AUTOSAR XML (schema 4-3-0)
package /Impl_SWC_DID_ARPkg
  swc implementation Impl_SWC_DID_type: programming-language=C, sw-version=1.0.0, vendor-id=0, behavior=SWC_DID_type_IB
    code-descriptors:
      code SRC: artifact-descriptors=autosar-engineering-object={short-label=EngObject, category=SWSRC}
    resource consumption ResourceConsumption
      memory section Mem_SWC_DID_CODE: size=0, sw-addrmethod=CODE, symbol=CODE
package /Interface_DID_ARPkg
  client server interface IF_DIDReadCDD
    18 x operation:
      CSOP_DIDGet_XWDMode
        4 x arg, all with server-argument-impl-policy=USE-ARGUMENT-TYPE:
          u8_XWDMode: type=uint8, direction=OUT
          u8_DIDSta_XWDMode: type=uint8, direction=OUT
          u16_DIDNum_XWDMode: type=uint16, direction=IN
          u16_DIDLen_XWDMode: type=uint16, direction=IN
      CSOP_DIDGet_DKCKey
        4 x arg, all with server-argument-impl-policy=USE-ARGUMENT-TYPE:
          u8Array8_DKCKey: type=u8Array8_DKCKey_type, direction=OUT
          u8_DIDSta_DKCKey: type=uint8, direction=OUT
          u16_DIDNum_DKCKey: type=uint16, direction=IN
          u16_DIDLen_DKCKey: type=uint16, direction=IN
      CSOP_DIDGet_DynoMode
        4 x arg, all with server-argument-impl-policy=USE-ARGUMENT-TYPE:
          u8_DynoMode: type=uint8, direction=OUT
          u8_DIDSta_DynoMode: type=uint8, direction=OUT
          u16_DIDNum_DynoMode: type=uint16, direction=IN
          u16_DIDLen_DynoMode: type=uint16, direction=IN
      CSOP_DIDGet_TurnLampFRThreCurr
        4 x arg, all with server-argument-impl-policy=USE-ARGUMENT-TYPE:
          u8_TurnLampFRThreCurr: type=uint8, direction=OUT
          u8_DIDSta_TurnLampFRThreCurr: type=uint8, direction=OUT
          u16_DIDNum_TurnLampFRThreCurr: type=uint16, direction=IN
          u16_DIDLen_TurnLampFRThreCurr: type=uint16, direction=IN
      CSOP_DIDGet_TurnLampRRThreCurr
        4 x arg, all with server-argument-impl-policy=USE-ARGUMENT-TYPE:
          u8_TurnLampRRThreCurr: type=uint8, direction=OUT
          u8_DIDSta_TurnLampRRThreCurr: type=uint8, direction=OUT
          u16_DIDNum_TurnLampRRThreCurr: type=uint16, direction=IN
          u16_DIDLen_TurnLampRRThreCurr: type=uint16, direction=IN
      CSOP_DIDGet_TurnLampFLThreCurr
        4 x arg, all with server-argument-impl-policy=USE-ARGUMENT-TYPE:
          u8_TurnLampFLThreCurr: type=uint8, direction=OUT
          u8_DIDSta_TurnLampFLThreCurr: type=uint8, direction=OUT
          u16_DIDNum_TurnLampFLThreCurr: type=uint16, direction=IN
          u16_DIDLen_TurnLampFLThreCurr: type=uint16, direction=IN
      CSOP_DIDGet_TurnLampRLThreCurr
        4 x arg, all with server-argument-impl-policy=USE-ARGUMENT-TYPE:
          u8_TurnLampRLThreCurr: type=uint8, direction=OUT
          u8_DIDSta_TurnLampRLThreCurr: type=uint8, direction=OUT
          u16_DIDNum_TurnLampRLThreCurr: type=uint16, direction=IN
          u16_DIDLen_TurnLampRLThreCurr: type=uint16, direction=IN
      CSOP_DIDGet_FMHTimer
        4 x arg, all with server-argument-impl-policy=USE-ARGUMENT-TYPE:
          u8_FMHTimer: type=uint8, direction=OUT
          u8_DIDSta_FMHTimer: type=uint8, direction=OUT
          u16_DIDNum_FMHTimer: type=uint16, direction=IN
          u16_DIDLen_FMHTimer: type=uint16, direction=IN
      CSOP_DIDGet_AutoLock
        4 x arg, all with server-argument-impl-policy=USE-ARGUMENT-TYPE:
          u8_AutoLock: type=uint8, direction=OUT
          u8_DIDSta_AutoLock: type=uint8, direction=OUT
          u16_DIDNum_AutoLock: type=uint16, direction=IN
          u16_DIDLen_AutoLock: type=uint16, direction=IN
      CSOP_DIDGet_DRLDis
        4 x arg, all with server-argument-impl-policy=USE-ARGUMENT-TYPE:
          u8_DRLDis: type=uint8, direction=OUT
          u8_DIDSta_DRLDis: type=uint8, direction=OUT
          u16_DIDNum_DRLDis: type=uint16, direction=IN
          u16_DIDLen_DRLDis: type=uint16, direction=IN
      CSOP_DIDGet_AutoWipHSpdEN
        4 x arg, all with server-argument-impl-policy=USE-ARGUMENT-TYPE:
          u8_AutoWipHSpdEN: type=uint8, direction=OUT
          u8_DIDSta_AutoWipHSpdEN: type=uint8, direction=OUT
          u16_DIDNum_AutoWipHSpdEN: type=uint16, direction=IN
          u16_DIDLen_AutoWipHSpdEN: type=uint16, direction=IN
      CSOP_DIDGet_WipRLSCmdHoldFilter
        4 x arg, all with server-argument-impl-policy=USE-ARGUMENT-TYPE:
          u8_WipRLSCmdHoldFilter: type=uint8, direction=OUT
          u8_DIDSta_WipRLSCmdHoldFilter: type=uint8, direction=OUT
          u16_DIDNum_WipRLSCmdHoldFilter: type=uint16, direction=IN
          u16_DIDLen_WipRLSCmdHoldFilter: type=uint16, direction=IN
      CSOP_DIDGet_WipRLSCmdCutFilter
        4 x arg, all with server-argument-impl-policy=USE-ARGUMENT-TYPE:
          u8_WipRLSCmdCutFilter: type=uint8, direction=OUT
          u8_DIDSta_WipRLSCmdCutFilter: type=uint8, direction=OUT
          u16_DIDNum_WipRLSCmdCutFilter: type=uint16, direction=IN
          u16_DIDLen_WipRLSCmdCutFilter: type=uint16, direction=IN
      CSOP_DIDGet_USSConfig
        4 x arg, all with server-argument-impl-policy=USE-ARGUMENT-TYPE:
          u8Array16_USSConfig: type=u8Array16_USSConfig_type, direction=OUT
          u8_DIDSta_USSConfig: type=uint8, direction=OUT
          u16_DIDNum_USSConfig: type=uint16, direction=IN
          u16_DIDLen_USSConfig: type=uint16, direction=IN
      CSOP_DIDGet_TireSize
        4 x arg, all with server-argument-impl-policy=USE-ARGUMENT-TYPE:
          u8Array16_TireSize: type=u8Array16_TireSize_type, direction=OUT
          u8_DIDSta_TireSize: type=uint8, direction=OUT
          u16_DIDNum_TireSize: type=uint16, direction=IN
          u16_DIDLen_TireSize: type=uint16, direction=IN
      CSOP_DIDGet_APSFunConfig
        4 x arg, all with server-argument-impl-policy=USE-ARGUMENT-TYPE:
          u8Array16_APSFunConfig: type=u8Array16_APSFunConfig_type, direction=OUT
          u8_DIDSta_APSFunConfig: type=uint8, direction=OUT
          u16_DIDNum_APSFunConfig: type=uint16, direction=IN
          u16_DIDLen_APSFunConfig: type=uint16, direction=IN
      CSOP_DIDGet_OBDReq
        4 x arg, all with server-argument-impl-policy=USE-ARGUMENT-TYPE:
          u8_OBDReq: type=uint8, direction=OUT
          u8_DIDSta_OBDReq: type=uint8, direction=OUT
          u16_DIDNum_OBDReq: type=uint16, direction=IN
          u16_DIDLen_OBDReq: type=uint16, direction=IN
      CSOP_DIDGet_TestGroup
        4 x arg, all with server-argument-impl-policy=USE-ARGUMENT-TYPE:
          u8Array12_TestGroup: type=u8Array12_TestGroup_type, direction=OUT
          u8_DIDSta_TestGroup: type=uint8, direction=OUT
          u16_DIDNum_TestGroup: type=uint16, direction=IN
          u16_DIDLen_TestGroup: type=uint16, direction=IN
  client server interface IF_DIDWriteCDD
    56 x operation:
      CSOP_DIDSet_XWDMode
        arg u16_DIDNum_XWDMode: type=uint16, direction=IN, server-argument-impl-policy=USE-ARGUMENT-TYPE
        arg u16_DIDLen_XWDMode: type=uint16, direction=IN, server-argument-impl-policy=USE-ARGUMENT-TYPE
        arg u8_XWDMode: type=uint8, direction=IN, server-argument-impl-policy=USE-ARGUMENT-TYPE
      CSOP_DIDSet_DKCKey
        arg u16_DIDNum_DKCKey: type=uint16, direction=IN, server-argument-impl-policy=USE-ARGUMENT-TYPE
        arg u16_DIDLen_DKCKey: type=uint16, direction=IN, server-argument-impl-policy=USE-ARGUMENT-TYPE
        arg u8Array8_DKCKey: type=u8Array8_DKCKey_type, direction=IN, server-argument-impl-policy=USE-ARGUMENT-TYPE
      CSOP_DIDSet_DynoMode
        arg u16_DIDNum_DynoMode: type=uint16, direction=IN, server-argument-impl-policy=USE-ARGUMENT-TYPE
        arg u16_DIDLen_DynoMode: type=uint16, direction=IN, server-argument-impl-policy=USE-ARGUMENT-TYPE
        arg u8_DynoMode: type=uint8, direction=IN, server-argument-impl-policy=USE-ARGUMENT-TYPE
      CSOP_DIDSet_APPPedalZP
        arg u16_DIDNum_APPPedalZP: type=uint16, direction=IN, server-argument-impl-policy=USE-ARGUMENT-TYPE
        arg u16_DIDLen_APPPedalZP: type=uint16, direction=IN, server-argument-impl-policy=USE-ARGUMENT-TYPE
        arg u8Array3_APPPedalZP: type=u8Array3_APPPedalZP_type, direction=IN, server-argument-impl-policy=USE-ARGUMENT-TYPE
      CSOP_DIDSet_NVMPedalZP
        arg u16_DIDNum_NVMPedalZP: type=uint16, direction=IN, server-argument-impl-policy=USE-ARGUMENT-TYPE
        arg u16_DIDLen_NVMPedalZP: type=uint16, direction=IN, server-argument-impl-policy=USE-ARGUMENT-TYPE
        arg u8Array3_NVMPedalZP: type=u8Array3_NVMPedalZP_type, direction=IN, server-argument-impl-policy=USE-ARGUMENT-TYPE
      CSOP_DIDSet_TurnLampFRThreCurr
        arg u16_DIDNum_TurnLampFRThreCurr: type=uint16, direction=IN, server-argument-impl-policy=USE-ARGUMENT-TYPE
        arg u16_DIDLen_TurnLampFRThreCurr: type=uint16, direction=IN, server-argument-impl-policy=USE-ARGUMENT-TYPE
        arg u8_TurnLampFRThreCurr: type=uint8, direction=IN, server-argument-impl-policy=USE-ARGUMENT-TYPE
      CSOP_DIDSet_TurnLampRRThreCurr
        arg u16_DIDNum_TurnLampRRThreCurr: type=uint16, direction=IN, server-argument-impl-policy=USE-ARGUMENT-TYPE
        arg u16_DIDLen_TurnLampRRThreCurr: type=uint16, direction=IN, server-argument-impl-policy=USE-ARGUMENT-TYPE
        arg u8_TurnLampRRThreCurr: type=uint8, direction=IN, server-argument-impl-policy=USE-ARGUMENT-TYPE
      CSOP_DIDSet_TurnLampFLThreCurr
        arg u16_DIDNum_TurnLampFLThreCurr: type=uint16, direction=IN, server-argument-impl-policy=USE-ARGUMENT-TYPE
        arg u16_DIDLen_TurnLampFLThreCurr: type=uint16, direction=IN, server-argument-impl-policy=USE-ARGUMENT-TYPE
        arg u8_TurnLampFLThreCurr: type=uint8, direction=IN, server-argument-impl-policy=USE-ARGUMENT-TYPE
      CSOP_DIDSet_TurnLampRLThreCurr
        arg u16_DIDNum_TurnLampRLThreCurr: type=uint16, direction=IN, server-argument-impl-policy=USE-ARGUMENT-TYPE
        arg u16_DIDLen_TurnLampRLThreCurr: type=uint16, direction=IN, server-argument-impl-policy=USE-ARGUMENT-TYPE
        arg u8_TurnLampRLThreCurr: type=uint8, direction=IN, server-argument-impl-policy=USE-ARGUMENT-TYPE
      CSOP_DIDSet_FMHTimer
        arg u16_DIDNum_FMHTimer: type=uint16, direction=IN, server-argument-impl-policy=USE-ARGUMENT-TYPE
        arg u16_DIDLen_FMHTimer: type=uint16, direction=IN, server-argument-impl-policy=USE-ARGUMENT-TYPE
        arg u8_FMHTimer: type=uint8, direction=IN, server-argument-impl-policy=USE-ARGUMENT-TYPE
      CSOP_DIDSet_AutoLock
        arg u16_DIDNum_AutoLock: type=uint16, direction=IN, server-argument-impl-policy=USE-ARGUMENT-TYPE
        arg u16_DIDLen_AutoLock: type=uint16, direction=IN, server-argument-impl-policy=USE-ARGUMENT-TYPE
        arg u8_AutoLock: type=uint8, direction=IN, server-argument-impl-policy=USE-ARGUMENT-TYPE
      CSOP_DIDSet_DRLDis
        arg u16_DIDNum_DRLDis: type=uint16, direction=IN, server-argument-impl-policy=USE-ARGUMENT-TYPE
        arg u16_DIDLen_DRLDis: type=uint16, direction=IN, server-argument-impl-policy=USE-ARGUMENT-TYPE
        arg u8_DRLDis: type=uint8, direction=IN, server-argument-impl-policy=USE-ARGUMENT-TYPE
      CSOP_DIDSet_AutoWipHSpdEN
        arg u16_DIDNum_AutoWipHSpdEN: type=uint16, direction=IN, server-argument-impl-policy=USE-ARGUMENT-TYPE
        arg u16_DIDLen_AutoWipHSpdEN: type=uint16, direction=IN, server-argument-impl-policy=USE-ARGUMENT-TYPE
        arg u8_AutoWipHSpdEN: type=uint8, direction=IN, server-argument-impl-policy=USE-ARGUMENT-TYPE
      CSOP_DIDSet_WipRLSCmdHoldFilter
        arg u16_DIDNum_WipRLSCmdHoldFilter: type=uint16, direction=IN, server-argument-impl-policy=USE-ARGUMENT-TYPE
        arg u16_DIDLen_WipRLSCmdHoldFilter: type=uint16, direction=IN, server-argument-impl-policy=USE-ARGUMENT-TYPE
        arg u8_WipRLSCmdHoldFilter: type=uint8, direction=IN, server-argument-impl-policy=USE-ARGUMENT-TYPE
      CSOP_DIDSet_WipRLSCmdCutFilter
        arg u16_DIDNum_WipRLSCmdCutFilter: type=uint16, direction=IN, server-argument-impl-policy=USE-ARGUMENT-TYPE
        arg u16_DIDLen_WipRLSCmdCutFilter: type=uint16, direction=IN, server-argument-impl-policy=USE-ARGUMENT-TYPE
        arg u8_WipRLSCmdCutFilter: type=uint8, direction=IN, server-argument-impl-policy=USE-ARGUMENT-TYPE
      CSOP_DIDSet_LFSensorID
        arg u16_DIDNum_LFSensorID: type=uint16, direction=IN, server-argument-impl-policy=USE-ARGUMENT-TYPE
        arg u16_DIDLen_LFSensorID: type=uint16, direction=IN, server-argument-impl-policy=USE-ARGUMENT-TYPE
        arg u8Array4_LFSensorID: type=u8Array4_LFSensorID_type, direction=IN, server-argument-impl-policy=USE-ARGUMENT-TYPE
      CSOP_DIDSet_RFSensorID
        arg u16_DIDNum_RFSensorID: type=uint16, direction=IN, server-argument-impl-policy=USE-ARGUMENT-TYPE
        arg u16_DIDLen_RFSensorID: type=uint16, direction=IN, server-argument-impl-policy=USE-ARGUMENT-TYPE
        arg u8Array4_RFSensorID: type=u8Array4_RFSensorID_type, direction=IN, server-argument-impl-policy=USE-ARGUMENT-TYPE
      CSOP_DIDSet_LRSensorID
        arg u16_DIDNum_LRSensorID: type=uint16, direction=IN, server-argument-impl-policy=USE-ARGUMENT-TYPE
        arg u16_DIDLen_LRSensorID: type=uint16, direction=IN, server-argument-impl-policy=USE-ARGUMENT-TYPE
        arg u8Array4_LRSensorID: type=u8Array4_LRSensorID_type, direction=IN, server-argument-impl-policy=USE-ARGUMENT-TYPE
      CSOP_DIDSet_RRSensorID
        arg u16_DIDNum_RRSensorID: type=uint16, direction=IN, server-argument-impl-policy=USE-ARGUMENT-TYPE
        arg u16_DIDLen_RRSensorID: type=uint16, direction=IN, server-argument-impl-policy=USE-ARGUMENT-TYPE
        arg u8Array4_RRSensorID: type=u8Array4_RRSensorID_type, direction=IN, server-argument-impl-policy=USE-ARGUMENT-TYPE
      CSOP_DIDSet_WhlPres
        arg u16_DIDNum_WhlPres: type=uint16, direction=IN, server-argument-impl-policy=USE-ARGUMENT-TYPE
        arg u16_DIDLen_WhlPres: type=uint16, direction=IN, server-argument-impl-policy=USE-ARGUMENT-TYPE
        arg u8Array4_WhlPres: type=u8Array4_WhlPres_type, direction=IN, server-argument-impl-policy=USE-ARGUMENT-TYPE
      CSOP_DIDSet_WhlTmp
        arg u16_DIDNum_WhlTmp: type=uint16, direction=IN, server-argument-impl-policy=USE-ARGUMENT-TYPE
        arg u16_DIDLen_WhlTmp: type=uint16, direction=IN, server-argument-impl-policy=USE-ARGUMENT-TYPE
        arg u8Array4_WhlTmp: type=u8Array4_WhlTmp_type, direction=IN, server-argument-impl-policy=USE-ARGUMENT-TYPE
      CSOP_DIDSet_WhlSensorBattSta
        arg u16_DIDNum_WhlSensorBattSta: type=uint16, direction=IN, server-argument-impl-policy=USE-ARGUMENT-TYPE
        arg u16_DIDLen_WhlSensorBattSta: type=uint16, direction=IN, server-argument-impl-policy=USE-ARGUMENT-TYPE
        arg u8_WhlSensorBattSta: type=uint8, direction=IN, server-argument-impl-policy=USE-ARGUMENT-TYPE
      CSOP_DIDSet_LFLowPresThre
        arg u16_DIDNum_LFLowPresThre: type=uint16, direction=IN, server-argument-impl-policy=USE-ARGUMENT-TYPE
        arg u16_DIDLen_LFLowPresThre: type=uint16, direction=IN, server-argument-impl-policy=USE-ARGUMENT-TYPE
        arg u8_LFLowPresThre: type=uint8, direction=IN, server-argument-impl-policy=USE-ARGUMENT-TYPE
      CSOP_DIDSet_RFLowPresThre
        arg u16_DIDNum_RFLowPresThre: type=uint16, direction=IN, server-argument-impl-policy=USE-ARGUMENT-TYPE
        arg u16_DIDLen_RFLowPresThre: type=uint16, direction=IN, server-argument-impl-policy=USE-ARGUMENT-TYPE
        arg u8_RFLowPresThre: type=uint8, direction=IN, server-argument-impl-policy=USE-ARGUMENT-TYPE
      CSOP_DIDSet_LRLowPresThre
        arg u16_DIDNum_LRLowPresThre: type=uint16, direction=IN, server-argument-impl-policy=USE-ARGUMENT-TYPE
        arg u16_DIDLen_LRLowPresThre: type=uint16, direction=IN, server-argument-impl-policy=USE-ARGUMENT-TYPE
        arg u8_LRLowPresThre: type=uint8, direction=IN, server-argument-impl-policy=USE-ARGUMENT-TYPE
      CSOP_DIDSet_RRLowPresThre
        arg u16_DIDNum_RRLowPresThre: type=uint16, direction=IN, server-argument-impl-policy=USE-ARGUMENT-TYPE
        arg u16_DIDLen_RRLowPresThre: type=uint16, direction=IN, server-argument-impl-policy=USE-ARGUMENT-TYPE
        arg u8_RRLowPresThre: type=uint8, direction=IN, server-argument-impl-policy=USE-ARGUMENT-TYPE
      CSOP_DIDSet_SensorMode
        arg u16_DIDNum_SensorMode: type=uint16, direction=IN, server-argument-impl-policy=USE-ARGUMENT-TYPE
        arg u16_DIDLen_SensorMode: type=uint16, direction=IN, server-argument-impl-policy=USE-ARGUMENT-TYPE
        arg u8_SensorMode: type=uint8, direction=IN, server-argument-impl-policy=USE-ARGUMENT-TYPE
      CSOP_DIDSet_TPMSLearnSta
        arg u16_DIDNum_TPMSLearnSta: type=uint16, direction=IN, server-argument-impl-policy=USE-ARGUMENT-TYPE
        arg u16_DIDLen_TPMSLearnSta: type=uint16, direction=IN, server-argument-impl-policy=USE-ARGUMENT-TYPE
        arg u8_TPMSLearnSta: type=uint8, direction=IN, server-argument-impl-policy=USE-ARGUMENT-TYPE
      CSOP_DIDSet_USSConfig
        arg u16_DIDNum_USSConfig: type=uint16, direction=IN, server-argument-impl-policy=USE-ARGUMENT-TYPE
        arg u16_DIDLen_USSConfig: type=uint16, direction=IN, server-argument-impl-policy=USE-ARGUMENT-TYPE
        arg u8Array16_USSConfig: type=u8Array16_USSConfig_type, direction=IN, server-argument-impl-policy=USE-ARGUMENT-TYPE
      CSOP_DIDSet_TireSize
        arg u16_DIDNum_TireSize: type=uint16, direction=IN, server-argument-impl-policy=USE-ARGUMENT-TYPE
        arg u16_DIDLen_TireSize: type=uint16, direction=IN, server-argument-impl-policy=USE-ARGUMENT-TYPE
        arg u8Array16_TireSize: type=u8Array16_TireSize_type, direction=IN, server-argument-impl-policy=USE-ARGUMENT-TYPE
      CSOP_DIDSet_APSFunConfig
        arg u16_DIDNum_APSFunConfig: type=uint16, direction=IN, server-argument-impl-policy=USE-ARGUMENT-TYPE
        arg u16_DIDLen_APSFunConfig: type=uint16, direction=IN, server-argument-impl-policy=USE-ARGUMENT-TYPE
        arg u8Array16_APSFunConfig: type=u8Array16_APSFunConfig_type, direction=IN, server-argument-impl-policy=USE-ARGUMENT-TYPE
      CSOP_DIDSet_VSS
        arg u16_DIDNum_VSS: type=uint16, direction=IN, server-argument-impl-policy=USE-ARGUMENT-TYPE
        arg u16_DIDLen_VSS: type=uint16, direction=IN, server-argument-impl-policy=USE-ARGUMENT-TYPE
        arg u8_VSS: type=uint8, direction=IN, server-argument-impl-policy=USE-ARGUMENT-TYPE
      CSOP_DIDSet_OBDReq
        arg u16_DIDNum_OBDReq: type=uint16, direction=IN, server-argument-impl-policy=USE-ARGUMENT-TYPE
        arg u16_DIDLen_OBDReq: type=uint16, direction=IN, server-argument-impl-policy=USE-ARGUMENT-TYPE
        arg u8_OBDReq: type=uint8, direction=IN, server-argument-impl-policy=USE-ARGUMENT-TYPE
      CSOP_DIDSet_RUNTM
        arg u16_DIDNum_RUNTM: type=uint16, direction=IN, server-argument-impl-policy=USE-ARGUMENT-TYPE
        arg u16_DIDLen_RUNTM: type=uint16, direction=IN, server-argument-impl-policy=USE-ARGUMENT-TYPE
        arg u8Array2_RUNTM: type=u8Array2_RUNTM_type, direction=IN, server-argument-impl-policy=USE-ARGUMENT-TYPE
      CSOP_DIDSet_MILDIST
        arg u16_DIDNum_MILDIST: type=uint16, direction=IN, server-argument-impl-policy=USE-ARGUMENT-TYPE
        arg u16_DIDLen_MILDIST: type=uint16, direction=IN, server-argument-impl-policy=USE-ARGUMENT-TYPE
        arg u8Array2_MILDIST: type=u8Array2_MILDIST_type, direction=IN, server-argument-impl-policy=USE-ARGUMENT-TYPE
      CSOP_DIDSet_CLRDIST
        arg u16_DIDNum_CLRDIST: type=uint16, direction=IN, server-argument-impl-policy=USE-ARGUMENT-TYPE
        arg u16_DIDLen_CLRDIST: type=uint16, direction=IN, server-argument-impl-policy=USE-ARGUMENT-TYPE
        arg u8Array2_CLRDIST: type=u8Array2_CLRDIST_type, direction=IN, server-argument-impl-policy=USE-ARGUMENT-TYPE
      CSOP_DIDSet_APPD
        arg u16_DIDNum_APPD: type=uint16, direction=IN, server-argument-impl-policy=USE-ARGUMENT-TYPE
        arg u16_DIDLen_APPD: type=uint16, direction=IN, server-argument-impl-policy=USE-ARGUMENT-TYPE
        arg u8_APPD: type=uint8, direction=IN, server-argument-impl-policy=USE-ARGUMENT-TYPE
      CSOP_DIDSet_APPE
        arg u16_DIDNum_APPE: type=uint16, direction=IN, server-argument-impl-policy=USE-ARGUMENT-TYPE
        arg u16_DIDLen_APPE: type=uint16, direction=IN, server-argument-impl-policy=USE-ARGUMENT-TYPE
        arg u8_APPE: type=uint8, direction=IN, server-argument-impl-policy=USE-ARGUMENT-TYPE
      CSOP_DIDSet_ODOMETER
        arg u16_DIDNum_ODOMETER: type=uint16, direction=IN, server-argument-impl-policy=USE-ARGUMENT-TYPE
        arg u16_DIDLen_ODOMETER: type=uint16, direction=IN, server-argument-impl-policy=USE-ARGUMENT-TYPE
        arg u8Array4_ODOMETER: type=u8Array4_ODOMETER_type, direction=IN, server-argument-impl-policy=USE-ARGUMENT-TYPE
      CSOP_DIDSet_NUMPSATRIPSFLTMEMCLR
        arg u16_DIDNum_NUMPSATRIPSFLTMEMCLR: type=uint16, direction=IN, server-argument-impl-policy=USE-ARGUMENT-TYPE
        arg u16_DIDLen_NUMPSATRIPSFLTMEMCLR: type=uint16, direction=IN, server-argument-impl-policy=USE-ARGUMENT-TYPE
        arg u8Array2_NUMPSATRIPSFLTMEMCLR: type=u8Array2_NUMPSATRIPSFLTMEMCLR_type, direction=IN, server-argument-impl-policy=USE-ARGUMENT-TYPE
      CSOP_DIDSet_VIN
        arg u16_DIDNum_VIN: type=uint16, direction=IN, server-argument-impl-policy=USE-ARGUMENT-TYPE
        arg u16_DIDLen_VIN: type=uint16, direction=IN, server-argument-impl-policy=USE-ARGUMENT-TYPE
        arg u8Array17_VIN: type=u8Array17_VIN_type, direction=IN, server-argument-impl-policy=USE-ARGUMENT-TYPE
      CSOP_DIDSet_CALID
        arg u16_DIDNum_CALID: type=uint16, direction=IN, server-argument-impl-policy=USE-ARGUMENT-TYPE
        arg u16_DIDLen_CALID: type=uint16, direction=IN, server-argument-impl-policy=USE-ARGUMENT-TYPE
        arg u8Array16_CALID: type=u8Array16_CALID_type, direction=IN, server-argument-impl-policy=USE-ARGUMENT-TYPE
      CSOP_DIDSet_ECUNAME
        arg u16_DIDNum_ECUNAME: type=uint16, direction=IN, server-argument-impl-policy=USE-ARGUMENT-TYPE
        arg u16_DIDLen_ECUNAME: type=uint16, direction=IN, server-argument-impl-policy=USE-ARGUMENT-TYPE
        arg u8Array20_ECUNAME: type=u8Array20_ECUNAME_type, direction=IN, server-argument-impl-policy=USE-ARGUMENT-TYPE
      CSOP_DIDSet_ProtocolId
        arg u16_DIDNum_ProtocolId: type=uint16, direction=IN, server-argument-impl-policy=USE-ARGUMENT-TYPE
        arg u16_DIDLen_ProtocolId: type=uint16, direction=IN, server-argument-impl-policy=USE-ARGUMENT-TYPE
        arg u8_ProtocolId: type=uint8, direction=IN, server-argument-impl-policy=USE-ARGUMENT-TYPE
      CSOP_DIDSet_TestGroup
        arg u16_DIDNum_TestGroup: type=uint16, direction=IN, server-argument-impl-policy=USE-ARGUMENT-TYPE
        arg u16_DIDLen_TestGroup: type=uint16, direction=IN, server-argument-impl-policy=USE-ARGUMENT-TYPE
        arg u8Array12_TestGroup: type=u8Array12_TestGroup_type, direction=IN, server-argument-impl-policy=USE-ARGUMENT-TYPE
      CSOP_DIDSet_PSA
        arg u16_DIDNum_PSA: type=uint16, direction=IN, server-argument-impl-policy=USE-ARGUMENT-TYPE
        arg u16_DIDLen_PSA: type=uint16, direction=IN, server-argument-impl-policy=USE-ARGUMENT-TYPE
        arg u8Array24_PSA: type=u8Array24_PSA_type, direction=IN, server-argument-impl-policy=USE-ARGUMENT-TYPE
      CSOP_DIDSet_PKE
        arg u16_DIDNum_PKE: type=uint16, direction=IN, server-argument-impl-policy=USE-ARGUMENT-TYPE
        arg u16_DIDLen_PKE: type=uint16, direction=IN, server-argument-impl-policy=USE-ARGUMENT-TYPE
        arg u8Array8_PKE: type=u8Array8_PKE_type, direction=IN, server-argument-impl-policy=USE-ARGUMENT-TYPE
      CSOP_DIDSet_CDEODT
        arg u16_DIDNum_CDEODT: type=uint16, direction=IN, server-argument-impl-policy=USE-ARGUMENT-TYPE
        arg u16_DIDLen_CDEODT: type=uint16, direction=IN, server-argument-impl-policy=USE-ARGUMENT-TYPE
        arg u8Array8_CDEODT: type=u8Array8_CDEODT_type, direction=IN, server-argument-impl-policy=USE-ARGUMENT-TYPE
      CSOP_DIDSet_QTYPSATRIPS
        arg u16_DIDNum_QTYPSATRIPS: type=uint16, direction=IN, server-argument-impl-policy=USE-ARGUMENT-TYPE
        arg u16_DIDLen_QTYPSATRIPS: type=uint16, direction=IN, server-argument-impl-policy=USE-ARGUMENT-TYPE
        arg u8Array8_QTYPSATRIPS: type=u8Array8_QTYPSATRIPS_type, direction=IN, server-argument-impl-policy=USE-ARGUMENT-TYPE
      CSOP_DIDSet_DKCSta
        arg u16_DIDNum_DKCSta: type=uint16, direction=IN, server-argument-impl-policy=USE-ARGUMENT-TYPE
        arg u16_DIDLen_DKCSta: type=uint16, direction=IN, server-argument-impl-policy=USE-ARGUMENT-TYPE
        arg u8Array2_DKCSta: type=u8Array2_DKCSta_type, direction=IN, server-argument-impl-policy=USE-ARGUMENT-TYPE
      CSOP_DIDSet_DKCBLESta
        arg u16_DIDNum_DKCBLESta: type=uint16, direction=IN, server-argument-impl-policy=USE-ARGUMENT-TYPE
        arg u16_DIDLen_DKCBLESta: type=uint16, direction=IN, server-argument-impl-policy=USE-ARGUMENT-TYPE
        arg u8Array2_DKCBLESta: type=u8Array2_DKCBLESta_type, direction=IN, server-argument-impl-policy=USE-ARGUMENT-TYPE
      CSOP_DIDSet_UWBAnchorSta
        arg u16_DIDNum_UWBAnchorSta: type=uint16, direction=IN, server-argument-impl-policy=USE-ARGUMENT-TYPE
        arg u16_DIDLen_UWBAnchorSta: type=uint16, direction=IN, server-argument-impl-policy=USE-ARGUMENT-TYPE
        arg u8Array93_UWBAnchorSta: type=u8Array93_UWBAnchorSta_type, direction=IN, server-argument-impl-policy=USE-ARGUMENT-TYPE
      CSOP_DIDSet_LIDAAnchorSta
        arg u16_DIDNum_LIDAAnchorSta: type=uint16, direction=IN, server-argument-impl-policy=USE-ARGUMENT-TYPE
        arg u16_DIDLen_LIDAAnchorSta: type=uint16, direction=IN, server-argument-impl-policy=USE-ARGUMENT-TYPE
        arg u8Array21_LIDAAnchorSta: type=u8Array21_LIDAAnchorSta_type, direction=IN, server-argument-impl-policy=USE-ARGUMENT-TYPE
      CSOP_DIDSet_DoorNFCAnchorSta
        arg u16_DIDNum_DoorNFCAnchorSta: type=uint16, direction=IN, server-argument-impl-policy=USE-ARGUMENT-TYPE
        arg u16_DIDLen_DoorNFCAnchorSta: type=uint16, direction=IN, server-argument-impl-policy=USE-ARGUMENT-TYPE
        arg u8Array21_DoorNFCAnchorSta: type=u8Array21_DoorNFCAnchorSta_type, direction=IN, server-argument-impl-policy=USE-ARGUMENT-TYPE
      CSOP_DIDSet_UIDSta
        arg u16_DIDNum_UIDSta: type=uint16, direction=IN, server-argument-impl-policy=USE-ARGUMENT-TYPE
        arg u16_DIDLen_UIDSta: type=uint16, direction=IN, server-argument-impl-policy=USE-ARGUMENT-TYPE
        arg u8Array26_UIDSta: type=u8Array26_UIDSta_type, direction=IN, server-argument-impl-policy=USE-ARGUMENT-TYPE
      CSOP_DIDSet_FDDKCCoordXY
        arg u16_DIDNum_FDDKCCoordXY: type=uint16, direction=IN, server-argument-impl-policy=USE-ARGUMENT-TYPE
        arg u16_DIDLen_FDDKCCoordXY: type=uint16, direction=IN, server-argument-impl-policy=USE-ARGUMENT-TYPE
        arg u8Array3_FDDKCCoordXY: type=u8Array3_FDDKCCoordXY_type, direction=IN, server-argument-impl-policy=USE-ARGUMENT-TYPE
package /SWC_DID_ARPkg
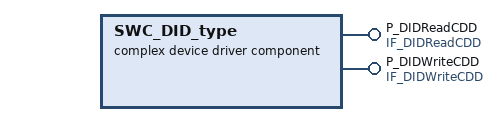
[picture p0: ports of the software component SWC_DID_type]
  complex device driver sw component type SWC_DID_type
    provide port P_DIDReadCDD: provided-interface=IF_DIDReadCDD
    provide port P_DIDWriteCDD: provided-interface=IF_DIDWriteCDD
    behavior SWC_DID_type_IB: handle-termination-and-restart=NO-SUPPORT
      74 x operation invoked event:
        oie_P_DIDReadCDD_CSOP_DIDGet_XWDMode: start-on-event=run_DIDGet_XWDMode, operation=P_DIDReadCDD.CSOP_DIDGet_XWDMode
        oie_P_DIDWriteCDD_CSOP_DIDSet_XWDMode: start-on-event=run_DIDSet_XWDMode, operation=P_DIDWriteCDD.CSOP_DIDSet_XWDMode
        oie_P_DIDReadCDD_CSOP_DIDGet_DKCKey: start-on-event=run_DIDGet_DKCKey, operation=P_DIDReadCDD.CSOP_DIDGet_DKCKey
        oie_P_DIDWriteCDD_CSOP_DIDSet_DKCKey: start-on-event=run_DIDSet_DKCKey, operation=P_DIDWriteCDD.CSOP_DIDSet_DKCKey
        oie_P_DIDReadCDD_CSOP_DIDGet_DynoMode: start-on-event=run_DIDGet_DynoMode, operation=P_DIDReadCDD.CSOP_DIDGet_DynoMode
        oie_P_DIDWriteCDD_CSOP_DIDSet_DynoMode: start-on-event=run_DIDSet_DynoMode, operation=P_DIDWriteCDD.CSOP_DIDSet_DynoMode
        oie_P_DIDWriteCDD_CSOP_DIDSet_APPPedalZP: start-on-event=run_DIDSet_APPPedalZP, operation=P_DIDWriteCDD.CSOP_DIDSet_APPPedalZP
        oie_P_DIDWriteCDD_CSOP_DIDSet_NVMPedalZP: start-on-event=run_DIDSet_NVMPedalZP, operation=P_DIDWriteCDD.CSOP_DIDSet_NVMPedalZP
        oie_P_DIDReadCDD_CSOP_DIDGet_TurnLampFRThreCurr: start-on-event=run_DIDGet_TurnLampFRThreCurr, operation=P_DIDReadCDD.CSOP_DIDGet_TurnLampFRThreCurr
        oie_P_DIDWriteCDD_CSOP_DIDSet_TurnLampFRThreCurr: start-on-event=run_DIDSet_TurnLampFRThreCurr, operation=P_DIDWriteCDD.CSOP_DIDSet_TurnLampFRThreCurr
        oie_P_DIDReadCDD_CSOP_DIDGet_TurnLampRRThreCurr: start-on-event=run_DIDGet_TurnLampRRThreCurr, operation=P_DIDReadCDD.CSOP_DIDGet_TurnLampRRThreCurr
        oie_P_DIDWriteCDD_CSOP_DIDSet_TurnLampRRThreCurr: start-on-event=run_DIDSet_TurnLampRRThreCurr, operation=P_DIDWriteCDD.CSOP_DIDSet_TurnLampRRThreCurr
        oie_P_DIDReadCDD_CSOP_DIDGet_TurnLampFLThreCurr: start-on-event=run_DIDGet_TurnLampFLThreCurr, operation=P_DIDReadCDD.CSOP_DIDGet_TurnLampFLThreCurr
        oie_P_DIDWriteCDD_CSOP_DIDSet_TurnLampFLThreCurr: start-on-event=run_DIDSet_TurnLampFLThreCurr, operation=P_DIDWriteCDD.CSOP_DIDSet_TurnLampFLThreCurr
        oie_P_DIDReadCDD_CSOP_DIDGet_TurnLampRLThreCurr: start-on-event=run_DIDGet_TurnLampRLThreCurr, operation=P_DIDReadCDD.CSOP_DIDGet_TurnLampRLThreCurr
        oie_P_DIDWriteCDD_CSOP_DIDSet_TurnLampRLThreCurr: start-on-event=run_DIDSet_TurnLampRLThreCurr, operation=P_DIDWriteCDD.CSOP_DIDSet_TurnLampRLThreCurr
        oie_P_DIDReadCDD_CSOP_DIDGet_FMHTimer: start-on-event=run_DIDGet_FMHTimer, operation=P_DIDReadCDD.CSOP_DIDGet_FMHTimer
        oie_P_DIDWriteCDD_CSOP_DIDSet_FMHTimer: start-on-event=run_DIDSet_FMHTimer, operation=P_DIDWriteCDD.CSOP_DIDSet_FMHTimer
        oie_P_DIDReadCDD_CSOP_DIDGet_AutoLock: start-on-event=run_DIDGet_AutoLock, operation=P_DIDReadCDD.CSOP_DIDGet_AutoLock
        oie_P_DIDWriteCDD_CSOP_DIDSet_AutoLock: start-on-event=run_DIDSet_AutoLock, operation=P_DIDWriteCDD.CSOP_DIDSet_AutoLock
        oie_P_DIDReadCDD_CSOP_DIDGet_DRLDis: start-on-event=run_DIDGet_DRLDis, operation=P_DIDReadCDD.CSOP_DIDGet_DRLDis
        oie_P_DIDWriteCDD_CSOP_DIDSet_DRLDis: start-on-event=run_DIDSet_DRLDis, operation=P_DIDWriteCDD.CSOP_DIDSet_DRLDis
        oie_P_DIDReadCDD_CSOP_DIDGet_AutoWipHSpdEN: start-on-event=run_DIDGet_AutoWipHSpdEN, operation=P_DIDReadCDD.CSOP_DIDGet_AutoWipHSpdEN
        oie_P_DIDWriteCDD_CSOP_DIDSet_AutoWipHSpdEN: start-on-event=run_DIDSet_AutoWipHSpdEN, operation=P_DIDWriteCDD.CSOP_DIDSet_AutoWipHSpdEN
        oie_P_DIDReadCDD_CSOP_DIDGet_WipRLSCmdHoldFilter: start-on-event=run_DIDGet_WipRLSCmdHoldFilter, operation=P_DIDReadCDD.CSOP_DIDGet_WipRLSCmdHoldFilter
        oie_P_DIDWriteCDD_CSOP_DIDSet_WipRLSCmdHoldFilter: start-on-event=run_DIDSet_WipRLSCmdHoldFilter, operation=P_DIDWriteCDD.CSOP_DIDSet_WipRLSCmdHoldFilter
        oie_P_DIDReadCDD_CSOP_DIDGet_WipRLSCmdCutFilter: start-on-event=run_DIDGet_WipRLSCmdCutFilter, operation=P_DIDReadCDD.CSOP_DIDGet_WipRLSCmdCutFilter
        oie_P_DIDWriteCDD_CSOP_DIDSet_WipRLSCmdCutFilter: start-on-event=run_DIDSet_WipRLSCmdCutFilter, operation=P_DIDWriteCDD.CSOP_DIDSet_WipRLSCmdCutFilter
        oie_P_DIDWriteCDD_CSOP_DIDSet_LFSensorID: start-on-event=run_DIDSet_LFSensorID, operation=P_DIDWriteCDD.CSOP_DIDSet_LFSensorID
        oie_P_DIDWriteCDD_CSOP_DIDSet_RFSensorID: start-on-event=run_DIDSet_RFSensorID, operation=P_DIDWriteCDD.CSOP_DIDSet_RFSensorID
        oie_P_DIDWriteCDD_CSOP_DIDSet_LRSensorID: start-on-event=run_DIDSet_LRSensorID, operation=P_DIDWriteCDD.CSOP_DIDSet_LRSensorID
        oie_P_DIDWriteCDD_CSOP_DIDSet_RRSensorID: start-on-event=run_DIDSet_RRSensorID, operation=P_DIDWriteCDD.CSOP_DIDSet_RRSensorID
        oie_P_DIDWriteCDD_CSOP_DIDSet_WhlPres: start-on-event=run_DIDSet_WhlPres, operation=P_DIDWriteCDD.CSOP_DIDSet_WhlPres
        oie_P_DIDWriteCDD_CSOP_DIDSet_WhlTmp: start-on-event=run_DIDSet_WhlTmp, operation=P_DIDWriteCDD.CSOP_DIDSet_WhlTmp
        oie_P_DIDWriteCDD_CSOP_DIDSet_WhlSensorBattSta: start-on-event=run_DIDSet_WhlSensorBattSta, operation=P_DIDWriteCDD.CSOP_DIDSet_WhlSensorBattSta
        oie_P_DIDWriteCDD_CSOP_DIDSet_LFLowPresThre: start-on-event=run_DIDSet_LFLowPresThre, operation=P_DIDWriteCDD.CSOP_DIDSet_LFLowPresThre
        oie_P_DIDWriteCDD_CSOP_DIDSet_RFLowPresThre: start-on-event=run_DIDSet_RFLowPresThre, operation=P_DIDWriteCDD.CSOP_DIDSet_RFLowPresThre
        oie_P_DIDWriteCDD_CSOP_DIDSet_LRLowPresThre: start-on-event=run_DIDSet_LRLowPresThre, operation=P_DIDWriteCDD.CSOP_DIDSet_LRLowPresThre
        oie_P_DIDWriteCDD_CSOP_DIDSet_RRLowPresThre: start-on-event=run_DIDSet_RRLowPresThre, operation=P_DIDWriteCDD.CSOP_DIDSet_RRLowPresThre
        oie_P_DIDWriteCDD_CSOP_DIDSet_SensorMode: start-on-event=run_DIDSet_SensorMode, operation=P_DIDWriteCDD.CSOP_DIDSet_SensorMode
        oie_P_DIDWriteCDD_CSOP_DIDSet_TPMSLearnSta: start-on-event=run_DIDSet_TPMSLearnSta, operation=P_DIDWriteCDD.CSOP_DIDSet_TPMSLearnSta
        oie_P_DIDReadCDD_CSOP_DIDGet_USSConfig: start-on-event=run_DIDGet_USSConfig, operation=P_DIDReadCDD.CSOP_DIDGet_USSConfig
        oie_P_DIDWriteCDD_CSOP_DIDSet_USSConfig: start-on-event=run_DIDSet_USSConfig, operation=P_DIDWriteCDD.CSOP_DIDSet_USSConfig
        oie_P_DIDReadCDD_CSOP_DIDGet_TireSize: start-on-event=run_DIDGet_TireSize, operation=P_DIDReadCDD.CSOP_DIDGet_TireSize
        oie_P_DIDWriteCDD_CSOP_DIDSet_TireSize: start-on-event=run_DIDSet_TireSize, operation=P_DIDWriteCDD.CSOP_DIDSet_TireSize
        oie_P_DIDReadCDD_CSOP_DIDGet_APSFunConfig: start-on-event=run_DIDGet_APSFunConfig, operation=P_DIDReadCDD.CSOP_DIDGet_APSFunConfig
        oie_P_DIDWriteCDD_CSOP_DIDSet_APSFunConfig: start-on-event=run_DIDSet_APSFunConfig, operation=P_DIDWriteCDD.CSOP_DIDSet_APSFunConfig
        oie_P_DIDWriteCDD_CSOP_DIDSet_VSS: start-on-event=run_DIDSet_VSS, operation=P_DIDWriteCDD.CSOP_DIDSet_VSS
        oie_P_DIDReadCDD_CSOP_DIDGet_OBDReq: start-on-event=run_DIDGet_OBDReq, operation=P_DIDReadCDD.CSOP_DIDGet_OBDReq
        oie_P_DIDWriteCDD_CSOP_DIDSet_OBDReq: start-on-event=run_DIDSet_OBDReq, operation=P_DIDWriteCDD.CSOP_DIDSet_OBDReq
        oie_P_DIDWriteCDD_CSOP_DIDSet_RUNTM: start-on-event=run_DIDSet_RUNTM, operation=P_DIDWriteCDD.CSOP_DIDSet_RUNTM
        oie_P_DIDWriteCDD_CSOP_DIDSet_MILDIST: start-on-event=run_DIDSet_MILDIST, operation=P_DIDWriteCDD.CSOP_DIDSet_MILDIST
        oie_P_DIDWriteCDD_CSOP_DIDSet_CLRDIST: start-on-event=run_DIDSet_CLRDIST, operation=P_DIDWriteCDD.CSOP_DIDSet_CLRDIST
        oie_P_DIDWriteCDD_CSOP_DIDSet_APPD: start-on-event=run_DIDSet_APPD, operation=P_DIDWriteCDD.CSOP_DIDSet_APPD
        oie_P_DIDWriteCDD_CSOP_DIDSet_APPE: start-on-event=run_DIDSet_APPE, operation=P_DIDWriteCDD.CSOP_DIDSet_APPE
        oie_P_DIDWriteCDD_CSOP_DIDSet_ODOMETER: start-on-event=run_DIDSet_ODOMETER, operation=P_DIDWriteCDD.CSOP_DIDSet_ODOMETER
        oie_P_DIDWriteCDD_CSOP_DIDSet_NUMPSATRIPSFLTMEMCLR: start-on-event=run_DIDSet_NUMPSATRIPSFLTMEMCLR, operation=P_DIDWriteCDD.CSOP_DIDSet_NUMPSATRIPSFLTMEMCLR
        oie_P_DIDWriteCDD_CSOP_DIDSet_VIN: start-on-event=run_DIDSet_VIN, operation=P_DIDWriteCDD.CSOP_DIDSet_VIN
        oie_P_DIDWriteCDD_CSOP_DIDSet_CALID: start-on-event=run_DIDSet_CALID, operation=P_DIDWriteCDD.CSOP_DIDSet_CALID
        oie_P_DIDWriteCDD_CSOP_DIDSet_ECUNAME: start-on-event=run_DIDSet_ECUNAME, operation=P_DIDWriteCDD.CSOP_DIDSet_ECUNAME
        oie_P_DIDWriteCDD_CSOP_DIDSet_ProtocolId: start-on-event=run_DIDSet_ProtocolId, operation=P_DIDWriteCDD.CSOP_DIDSet_ProtocolId
        oie_P_DIDReadCDD_CSOP_DIDGet_TestGroup: start-on-event=run_DIDGet_TestGroup, operation=P_DIDReadCDD.CSOP_DIDGet_TestGroup
        oie_P_DIDWriteCDD_CSOP_DIDSet_TestGroup: start-on-event=run_DIDSet_TestGroup, operation=P_DIDWriteCDD.CSOP_DIDSet_TestGroup
        oie_P_DIDWriteCDD_CSOP_DIDSet_PSA: start-on-event=run_DIDSet_PSA, operation=P_DIDWriteCDD.CSOP_DIDSet_PSA
        oie_P_DIDWriteCDD_CSOP_DIDSet_PKE: start-on-event=run_DIDSet_PKE, operation=P_DIDWriteCDD.CSOP_DIDSet_PKE
        oie_P_DIDWriteCDD_CSOP_DIDSet_CDEODT: start-on-event=run_DIDSet_CDEODT, operation=P_DIDWriteCDD.CSOP_DIDSet_CDEODT
        oie_P_DIDWriteCDD_CSOP_DIDSet_QTYPSATRIPS: start-on-event=run_DIDSet_QTYPSATRIPS, operation=P_DIDWriteCDD.CSOP_DIDSet_QTYPSATRIPS
        oie_P_DIDWriteCDD_CSOP_DIDSet_DKCSta: start-on-event=run_DIDSet_DKCSta, operation=P_DIDWriteCDD.CSOP_DIDSet_DKCSta
        oie_P_DIDWriteCDD_CSOP_DIDSet_DKCBLESta: start-on-event=run_DIDSet_DKCBLESta, operation=P_DIDWriteCDD.CSOP_DIDSet_DKCBLESta
        oie_P_DIDWriteCDD_CSOP_DIDSet_UWBAnchorSta: start-on-event=run_DIDSet_UWBAnchorSta, operation=P_DIDWriteCDD.CSOP_DIDSet_UWBAnchorSta
        oie_P_DIDWriteCDD_CSOP_DIDSet_LIDAAnchorSta: start-on-event=run_DIDSet_LIDAAnchorSta, operation=P_DIDWriteCDD.CSOP_DIDSet_LIDAAnchorSta
        oie_P_DIDWriteCDD_CSOP_DIDSet_DoorNFCAnchorSta: start-on-event=run_DIDSet_DoorNFCAnchorSta, operation=P_DIDWriteCDD.CSOP_DIDSet_DoorNFCAnchorSta
        oie_P_DIDWriteCDD_CSOP_DIDSet_UIDSta: start-on-event=run_DIDSet_UIDSta, operation=P_DIDWriteCDD.CSOP_DIDSet_UIDSta
        oie_P_DIDWriteCDD_CSOP_DIDSet_FDDKCCoordXY: start-on-event=run_DIDSet_FDDKCCoordXY, operation=P_DIDWriteCDD.CSOP_DIDSet_FDDKCCoordXY
      port-api-options:
        enable-take-address=false, indirect-api=false, port=P_DIDWriteCDD
        enable-take-address=false, indirect-api=false, port=P_DIDReadCDD
      74 x runnable:
        run_DIDGet_XWDMode
        run_DIDSet_XWDMode
        run_DIDGet_DKCKey
        run_DIDSet_DKCKey
        run_DIDGet_DynoMode
        run_DIDSet_DynoMode
        run_DIDSet_APPPedalZP
        run_DIDSet_NVMPedalZP
        run_DIDGet_TurnLampFRThreCurr
        run_DIDSet_TurnLampFRThreCurr
        run_DIDGet_TurnLampRRThreCurr
        run_DIDSet_TurnLampRRThreCurr
        run_DIDGet_TurnLampFLThreCurr
        run_DIDSet_TurnLampFLThreCurr
        run_DIDGet_TurnLampRLThreCurr
        run_DIDSet_TurnLampRLThreCurr
        run_DIDGet_FMHTimer
        run_DIDSet_FMHTimer
        run_DIDGet_AutoLock
        run_DIDSet_AutoLock
        run_DIDGet_DRLDis
        run_DIDSet_DRLDis
        run_DIDGet_AutoWipHSpdEN
        run_DIDSet_AutoWipHSpdEN
        run_DIDGet_WipRLSCmdHoldFilter
        run_DIDSet_WipRLSCmdHoldFilter
        run_DIDGet_WipRLSCmdCutFilter
        run_DIDSet_WipRLSCmdCutFilter
        run_DIDSet_LFSensorID
        run_DIDSet_RFSensorID
        run_DIDSet_LRSensorID
        run_DIDSet_RRSensorID
        run_DIDSet_WhlPres
        run_DIDSet_WhlTmp
        run_DIDSet_WhlSensorBattSta
        run_DIDSet_LFLowPresThre
        run_DIDSet_RFLowPresThre
        run_DIDSet_LRLowPresThre
        run_DIDSet_RRLowPresThre
        run_DIDSet_SensorMode
        run_DIDSet_TPMSLearnSta
        run_DIDGet_USSConfig
        run_DIDSet_USSConfig
        run_DIDGet_TireSize
        run_DIDSet_TireSize
        run_DIDGet_APSFunConfig
        run_DIDSet_APSFunConfig
        run_DIDSet_VSS
        run_DIDGet_OBDReq
        run_DIDSet_OBDReq
        run_DIDSet_RUNTM
        run_DIDSet_MILDIST
        run_DIDSet_CLRDIST
        run_DIDSet_APPD
        run_DIDSet_APPE
        run_DIDSet_ODOMETER
        run_DIDSet_NUMPSATRIPSFLTMEMCLR
        run_DIDSet_VIN
        run_DIDSet_CALID
        run_DIDSet_ECUNAME
        run_DIDSet_ProtocolId
        run_DIDGet_TestGroup
        run_DIDSet_TestGroup
        run_DIDSet_PSA
        run_DIDSet_PKE
        run_DIDSet_CDEODT
        run_DIDSet_QTYPSATRIPS
        run_DIDSet_DKCSta
        run_DIDSet_DKCBLESta
        run_DIDSet_UWBAnchorSta
        run_DIDSet_LIDAAnchorSta
        run_DIDSet_DoorNFCAnchorSta
        run_DIDSet_UIDSta
        run_DIDSet_FDDKCCoordXY
package /TypeDef_DID_ARPkg
  32 x impl type, all with category=ARRAY:
    u8Array8_DKCKey_type
      element u8_Element: category=VALUE, array-size=8, array-size-semantics=FIXED-SIZE, base-type=uint8
    u8Array3_APPPedalZP_type
      element u8_Element: category=VALUE, array-size=3, array-size-semantics=FIXED-SIZE, base-type=uint8
    u8Array3_NVMPedalZP_type
      element u8_Element: category=VALUE, array-size=3, array-size-semantics=FIXED-SIZE, base-type=uint8
    u8Array4_LFSensorID_type
      element u8_Element: category=VALUE, array-size=4, array-size-semantics=FIXED-SIZE, base-type=uint8
    u8Array4_RFSensorID_type
      element u8_Element: category=VALUE, array-size=4, array-size-semantics=FIXED-SIZE, base-type=uint8
    u8Array4_LRSensorID_type
      element u8_Element: category=VALUE, array-size=4, array-size-semantics=FIXED-SIZE, base-type=uint8
    u8Array4_RRSensorID_type
      element u8_Element: category=VALUE, array-size=4, array-size-semantics=FIXED-SIZE, base-type=uint8
    u8Array4_WhlPres_type
      element u8_Element: category=VALUE, array-size=4, array-size-semantics=FIXED-SIZE, base-type=uint8
    u8Array4_WhlTmp_type
      element u8_Element: category=VALUE, array-size=4, array-size-semantics=FIXED-SIZE, base-type=uint8
    u8Array16_USSConfig_type
      element u8_Element: category=VALUE, array-size=16, array-size-semantics=FIXED-SIZE, base-type=uint8
    u8Array16_TireSize_type
      element u8_Element: category=VALUE, array-size=16, array-size-semantics=FIXED-SIZE, base-type=uint8
    u8Array16_APSFunConfig_type
      element u8_Element: category=VALUE, array-size=16, array-size-semantics=FIXED-SIZE, base-type=uint8
    u8Array2_RUNTM_type
      element u8_Element: category=VALUE, array-size=2, array-size-semantics=FIXED-SIZE, base-type=uint8
    u8Array2_MILDIST_type
      element u8_Element: category=VALUE, array-size=2, array-size-semantics=FIXED-SIZE, base-type=uint8
    u8Array2_CLRDIST_type
      element u8_Element: category=VALUE, array-size=2, array-size-semantics=FIXED-SIZE, base-type=uint8
    u8Array4_ODOMETER_type
      element u8_Element: category=VALUE, array-size=4, array-size-semantics=FIXED-SIZE, base-type=uint8
    u8Array2_NUMPSATRIPSFLTMEMCLR_type
      element u8_Element: category=VALUE, array-size=2, array-size-semantics=FIXED-SIZE, base-type=uint8
    u8Array17_VIN_type
      element u8_Element: category=VALUE, array-size=17, array-size-semantics=FIXED-SIZE, base-type=uint8
    u8Array16_CALID_type
      element u8_Element: category=VALUE, array-size=16, array-size-semantics=FIXED-SIZE, base-type=uint8
    u8Array20_ECUNAME_type
      element u8_Element: category=VALUE, array-size=20, array-size-semantics=FIXED-SIZE, base-type=uint8
    u8Array12_TestGroup_type
      element u8_Element: category=VALUE, array-size=12, array-size-semantics=FIXED-SIZE, base-type=uint8
    u8Array24_PSA_type
      element u8_Element: category=VALUE, array-size=24, array-size-semantics=FIXED-SIZE, base-type=uint8
    u8Array8_PKE_type
      element u8_Element: category=VALUE, array-size=8, array-size-semantics=FIXED-SIZE, base-type=uint8
    u8Array8_CDEODT_type
      element u8_Element: category=VALUE, array-size=8, array-size-semantics=FIXED-SIZE, base-type=uint8
    u8Array8_QTYPSATRIPS_type
      element u8_Element: category=VALUE, array-size=8, array-size-semantics=FIXED-SIZE, base-type=uint8
    u8Array2_DKCSta_type
      element u8_Element: category=VALUE, array-size=2, array-size-semantics=FIXED-SIZE, base-type=uint8
    u8Array2_DKCBLESta_type
      element u8_Element: category=VALUE, array-size=2, array-size-semantics=FIXED-SIZE, base-type=uint8
    u8Array93_UWBAnchorSta_type
      element u8_Element: category=VALUE, array-size=93, array-size-semantics=FIXED-SIZE, base-type=uint8
    u8Array21_LIDAAnchorSta_type
      element u8_Element: category=VALUE, array-size=21, array-size-semantics=FIXED-SIZE, base-type=uint8
    u8Array21_DoorNFCAnchorSta_type
      element u8_Element: category=VALUE, array-size=21, array-size-semantics=FIXED-SIZE, base-type=uint8
    u8Array26_UIDSta_type
      element u8_Element: category=VALUE, array-size=26, array-size-semantics=FIXED-SIZE, base-type=uint8
    u8Array3_FDDKCCoordXY_type
      element u8_Element: category=VALUE, array-size=3, array-size-semantics=FIXED-SIZE, base-type=uint8
